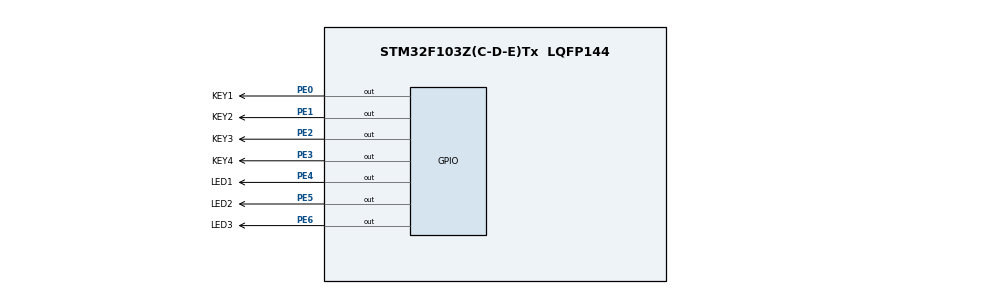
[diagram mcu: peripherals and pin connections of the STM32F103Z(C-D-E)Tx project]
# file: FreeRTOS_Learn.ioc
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Mcu.Family=STM32F1
Mcu.Name=STM32F103Z(C-D-E)Tx
Mcu.Package=LQFP144
NVIC.PriorityGroup=NVIC_PRIORITYGROUP_4
NVIC.TIM2_IRQn=true\:4\:0\:true\:false\:true\:true\:true
NVIC.TIM3_IRQn=true\:6\:0\:true\:false\:true\:true\:true
PA13.Mode=Serial_Wire
PA13.Signal=SYS_JTMS-SWDIO
PA14.Mode=Serial_Wire
PA14.Signal=SYS_JTCK-SWCLK
PE0.GPIO_Label=KEY1
PE0.GPIO_Speed=GPIO_SPEED_FREQ_HIGH
PE0.PinState=GPIO_PIN_SET
PE0.Signal=GPIO_Output
PE1.GPIO_Label=KEY2
PE1.GPIO_Speed=GPIO_SPEED_FREQ_HIGH
PE1.PinState=GPIO_PIN_SET
PE1.Signal=GPIO_Output
PE2.GPIO_Label=KEY3
PE2.GPIO_Speed=GPIO_SPEED_FREQ_HIGH
PE2.PinState=GPIO_PIN_SET
PE2.Signal=GPIO_Output
PE3.GPIO_Label=KEY4
PE3.GPIO_Speed=GPIO_SPEED_FREQ_HIGH
PE3.PinState=GPIO_PIN_SET
PE3.Signal=GPIO_Output
PE4.GPIO_Label=LED1
PE4.Signal=GPIO_Output
PE5.GPIO_Label=LED2
PE5.Signal=GPIO_Output
PE6.GPIO_Label=LED3
PE6.Signal=GPIO_Output
ProjectManager.HeapSize=0x200
ProjectManager.StackSize=0x400
ProjectManager.TargetToolchain=MDK-ARM V5.27
RCC.APB1Freq_Value=8000000
RCC.APB2Freq_Value=8000000
TIM2.Period=10000-1
TIM2.Prescaler=7200-1
TIM3.Period=10000-1
TIM3.Prescaler=7200-1
VP_TIM2_VS_ClockSourceINT.Mode=Internal
VP_TIM3_VS_ClockSourceINT.Mode=Internal
board=custom

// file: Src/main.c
/* USER CODE BEGIN Header */
/**
  ******************************************************************************
  * @file           : main.c
  * @brief          : Main program body
  ******************************************************************************
  * @attention
  *
  * <h2><center>&copy; Copyright (c) 2024 STMicroelectronics.
  * All rights reserved.</center></h2>
  *
  * This software component is licensed by ST under BSD 3-Clause license,
  * the "License"; You may not use this file except in compliance with the
  * License. You may obtain a copy of the License at:
  *                        opensource.org/licenses/BSD-3-Clause
  *
  ******************************************************************************
  */
/* USER CODE END Header */

#include "main.h"

/* USER CODE BEGIN Includes */
#include "freertos_demo.h"
/* USER CODE END Includes */

TIM_HandleTypeDef htim2;
TIM_HandleTypeDef htim3;

void SystemClock_Config(void);
static void MX_GPIO_Init(void);
static void MX_TIM2_Init(void);
static void MX_TIM3_Init(void);

/* USER CODE BEGIN 0 */
void HAL_TIM_PeriodElapsedCallback(TIM_HandleTypeDef *htim)
{
  if (htim->Instance == TIM2)
  {
    /* code */
    HAL_GPIO_TogglePin(LED1_GPIO_Port,LED1_Pin);
  }
  else  if (htim->Instance == TIM3)
  {
    /* code */
    HAL_GPIO_TogglePin(LED2_GPIO_Port,LED2_Pin);
  }

}
/* USER CODE END 0 */

int main(void)
{

  /* MCU Configuration--------------------------------------------------------*/

  /* Reset of all peripherals, Initializes the Flash interface and the Systick. */
  HAL_Init();

  /* Configure the system clock */
  SystemClock_Config();

  /* Initialize all configured peripherals */
  MX_GPIO_Init();
  MX_TIM2_Init();
  MX_TIM3_Init();
  /* USER CODE BEGIN 2 */
  HAL_TIM_Base_Start_IT(&htim2);
  HAL_TIM_Base_Start_IT(&htim3);
  freertos_demo();

  /* USER CODE END 2 */

  /* Infinite loop */
  /* USER CODE BEGIN WHILE */
//  while (1)
//  {
    /* USER CODE END WHILE */

    /* USER CODE BEGIN 3 */
//		HAL_GPIO_TogglePin(GPIOE,GPIO_PIN_4);
//		HAL_Delay(1000);
//		HAL_GPIO_TogglePin(GPIOE,GPIO_PIN_5);
//		HAL_Delay(1000);
//  }
  /* USER CODE END 3 */
}

void SystemClock_Config(void)
{
  RCC_OscInitTypeDef RCC_OscInitStruct = {0};
  RCC_ClkInitTypeDef RCC_ClkInitStruct = {0};

  /** Initializes the CPU, AHB and APB busses clocks
  */
  RCC_OscInitStruct.OscillatorType = RCC_OSCILLATORTYPE_HSI;
  RCC_OscInitStruct.HSIState = RCC_HSI_ON;
  RCC_OscInitStruct.HSICalibrationValue = RCC_HSICALIBRATION_DEFAULT;
  RCC_OscInitStruct.PLL.PLLState = RCC_PLL_NONE;
  if (HAL_RCC_OscConfig(&RCC_OscInitStruct) != HAL_OK)
  {
    Error_Handler();
  }
  /** Initializes the CPU, AHB and APB busses clocks
  */
  RCC_ClkInitStruct.ClockType = RCC_CLOCKTYPE_HCLK|RCC_CLOCKTYPE_SYSCLK
                              |RCC_CLOCKTYPE_PCLK1|RCC_CLOCKTYPE_PCLK2;
  RCC_ClkInitStruct.SYSCLKSource = RCC_SYSCLKSOURCE_HSI;
  RCC_ClkInitStruct.AHBCLKDivider = RCC_SYSCLK_DIV1;
  RCC_ClkInitStruct.APB1CLKDivider = RCC_HCLK_DIV1;
  RCC_ClkInitStruct.APB2CLKDivider = RCC_HCLK_DIV1;

  if (HAL_RCC_ClockConfig(&RCC_ClkInitStruct, FLASH_LATENCY_0) != HAL_OK)
  {
    Error_Handler();
  }
}

static void MX_TIM2_Init(void)
{

  TIM_ClockConfigTypeDef sClockSourceConfig = {0};
  TIM_MasterConfigTypeDef sMasterConfig = {0};

  htim2.Instance = TIM2;
  htim2.Init.Prescaler = 3600-1;
  htim2.Init.CounterMode = TIM_COUNTERMODE_UP;
  htim2.Init.Period = 10000-1;
  htim2.Init.ClockDivision = TIM_CLOCKDIVISION_DIV1;
  htim2.Init.AutoReloadPreload = TIM_AUTORELOAD_PRELOAD_DISABLE;
  if (HAL_TIM_Base_Init(&htim2) != HAL_OK)
  {
    Error_Handler();
  }
  sClockSourceConfig.ClockSource = TIM_CLOCKSOURCE_INTERNAL;
  if (HAL_TIM_ConfigClockSource(&htim2, &sClockSourceConfig) != HAL_OK)
  {
    Error_Handler();
  }
  sMasterConfig.MasterOutputTrigger = TIM_TRGO_RESET;
  sMasterConfig.MasterSlaveMode = TIM_MASTERSLAVEMODE_DISABLE;
  if (HAL_TIMEx_MasterConfigSynchronization(&htim2, &sMasterConfig) != HAL_OK)
  {
    Error_Handler();
  }

}

static void MX_TIM3_Init(void)
{

  TIM_ClockConfigTypeDef sClockSourceConfig = {0};
  TIM_MasterConfigTypeDef sMasterConfig = {0};

  htim3.Instance = TIM3;
  htim3.Init.Prescaler = 7200-1;
  htim3.Init.CounterMode = TIM_COUNTERMODE_UP;
  htim3.Init.Period = 10000-1;
  htim3.Init.ClockDivision = TIM_CLOCKDIVISION_DIV1;
  htim3.Init.AutoReloadPreload = TIM_AUTORELOAD_PRELOAD_DISABLE;
  if (HAL_TIM_Base_Init(&htim3) != HAL_OK)
  {
    Error_Handler();
  }
  sClockSourceConfig.ClockSource = TIM_CLOCKSOURCE_INTERNAL;
  if (HAL_TIM_ConfigClockSource(&htim3, &sClockSourceConfig) != HAL_OK)
  {
    Error_Handler();
  }
  sMasterConfig.MasterOutputTrigger = TIM_TRGO_RESET;
  sMasterConfig.MasterSlaveMode = TIM_MASTERSLAVEMODE_DISABLE;
  if (HAL_TIMEx_MasterConfigSynchronization(&htim3, &sMasterConfig) != HAL_OK)
  {
    Error_Handler();
  }

}

static void MX_GPIO_Init(void)
{
  GPIO_InitTypeDef GPIO_InitStruct = {0};

  /* GPIO Ports Clock Enable */
  __HAL_RCC_GPIOE_CLK_ENABLE();
  __HAL_RCC_GPIOA_CLK_ENABLE();

  /*Configure GPIO pin Output Level */
  HAL_GPIO_WritePin(GPIOE, KEY3_Pin|KEY4_Pin|KEY1_Pin|KEY2_Pin, GPIO_PIN_SET);

  /*Configure GPIO pin Output Level */
  HAL_GPIO_WritePin(GPIOE, LED1_Pin|LED2_Pin|LED3_Pin, GPIO_PIN_RESET);

  /*Configure GPIO pins : KEY3_Pin KEY4_Pin KEY1_Pin KEY2_Pin */
  GPIO_InitStruct.Pin = KEY3_Pin|KEY4_Pin|KEY1_Pin|KEY2_Pin;
  GPIO_InitStruct.Mode = GPIO_MODE_OUTPUT_PP;
  GPIO_InitStruct.Pull = GPIO_NOPULL;
  GPIO_InitStruct.Speed = GPIO_SPEED_FREQ_HIGH;
  HAL_GPIO_Init(GPIOE, &GPIO_InitStruct);

  /*Configure GPIO pins : LED1_Pin LED2_Pin LED3_Pin */
  GPIO_InitStruct.Pin = LED1_Pin|LED2_Pin|LED3_Pin;
  GPIO_InitStruct.Mode = GPIO_MODE_OUTPUT_PP;
  GPIO_InitStruct.Pull = GPIO_NOPULL;
  GPIO_InitStruct.Speed = GPIO_SPEED_FREQ_LOW;
  HAL_GPIO_Init(GPIOE, &GPIO_InitStruct);

}

void Error_Handler(void)
{
}

/************************ (C) COPYRIGHT STMicroelectronics *****END OF FILE****/
